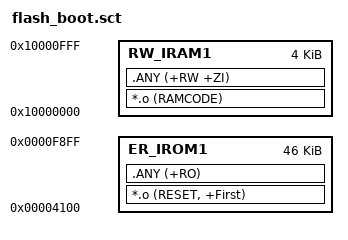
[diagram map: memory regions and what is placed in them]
; *************************************************************
; *** Scatter-Loading Description File generated by uVision ***
; *************************************************************

LR_IROM1 0x00004100 0x0000B800  {    ; load region size_region
  ER_IROM1 0x00004100 0x0000B800  {  ; load address = execution address
   *.o (RESET, +First)
   .ANY (+RO)
  }
  RW_IRAM1 0x10000000 0x00001000  {  ; RW data
   *.o (RAMCODE)
   .ANY (+RW +ZI)
  }
}

